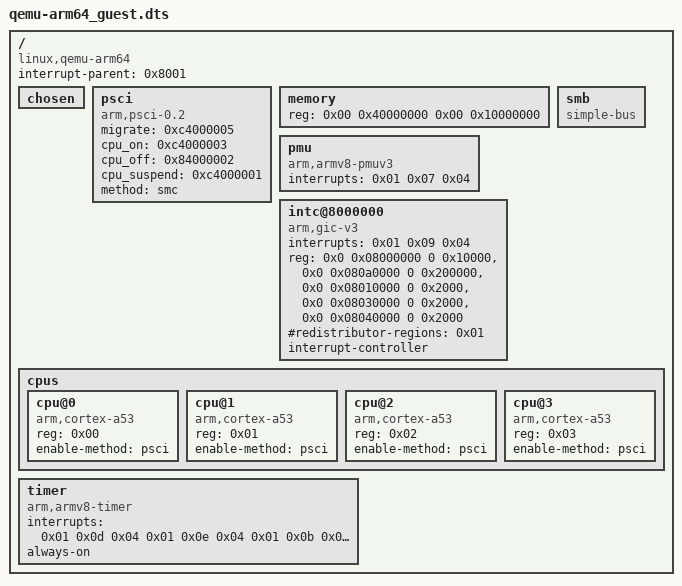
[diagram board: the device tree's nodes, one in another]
/dts-v1/;

/ {
	interrupt-parent = < 0x8001 >;
	#size-cells = < 0x02 >;
	#address-cells = < 0x02 >;
	compatible = "linux,qemu-arm64";

	chosen {
	};

	psci {
		migrate = < 0xc4000005 >;
		cpu_on = < 0xc4000003 >;
		cpu_off = < 0x84000002 >;
		cpu_suspend = < 0xc4000001 >;
		method = "smc";
		compatible = "arm,psci-0.2\0arm,psci";
	};

	memory {
		device_type = "memory";
		reg = <0x00 0x40000000 0x00 0x10000000>;
	};

	smb {
	compatible = "simple-bus";
	#address-cells = <0x01>;
	#size-cells = <0x01>;
	ranges;
	};

	pmu {
		interrupts = < 0x01 0x07 0x04 >;
		compatible = "arm,armv8-pmuv3";
	};

	intc@8000000 {
		phandle = < 0x8001 >;
		interrupts = < 0x01 0x09 0x04 >;
		reg = <0x0 0x08000000 0 0x10000>,	// GICD
		      <0x0 0x080a0000 0 0x200000>,	// GICR
		      <0x0 0x08010000 0 0x2000>,	// GICC
		      <0x0 0x08030000 0 0x2000>,	// GICH
		      <0x0 0x08040000 0 0x2000>;	// GICV
		#redistributor-regions = < 0x01 >;
		compatible = "arm,gic-v3";
		ranges;
		#size-cells = < 0x02 >;
		#address-cells = < 0x02 >;
		interrupt-controller;
		#interrupt-cells = < 0x03 >;
	};

	cpus {
		#size-cells = < 0x00 >;
		#address-cells = < 0x01 >;

		cpu@0 {
			reg = < 0x00 >;
			enable-method = "psci";
			compatible = "arm,cortex-a53";
			device_type = "cpu";
		};

		cpu@1 {
			reg = < 0x01 >;
			enable-method = "psci";
			compatible = "arm,cortex-a53";
			device_type = "cpu";
		};

		cpu@2 {
			reg = < 0x02 >;
			enable-method = "psci";
			compatible = "arm,cortex-a53";
			device_type = "cpu";
		};

		cpu@3 {
			reg = < 0x03 >;
			enable-method = "psci";
			compatible = "arm,cortex-a53";
			device_type = "cpu";
		};
	};

	timer {
		interrupts = < 0x01 0x0d 0x04 0x01 0x0e 0x04 0x01 0x0b 0x04 0x01 0x0a 0x04 >;
		always-on;
		compatible = "arm,armv8-timer\0arm,armv7-timer";
	};
};
